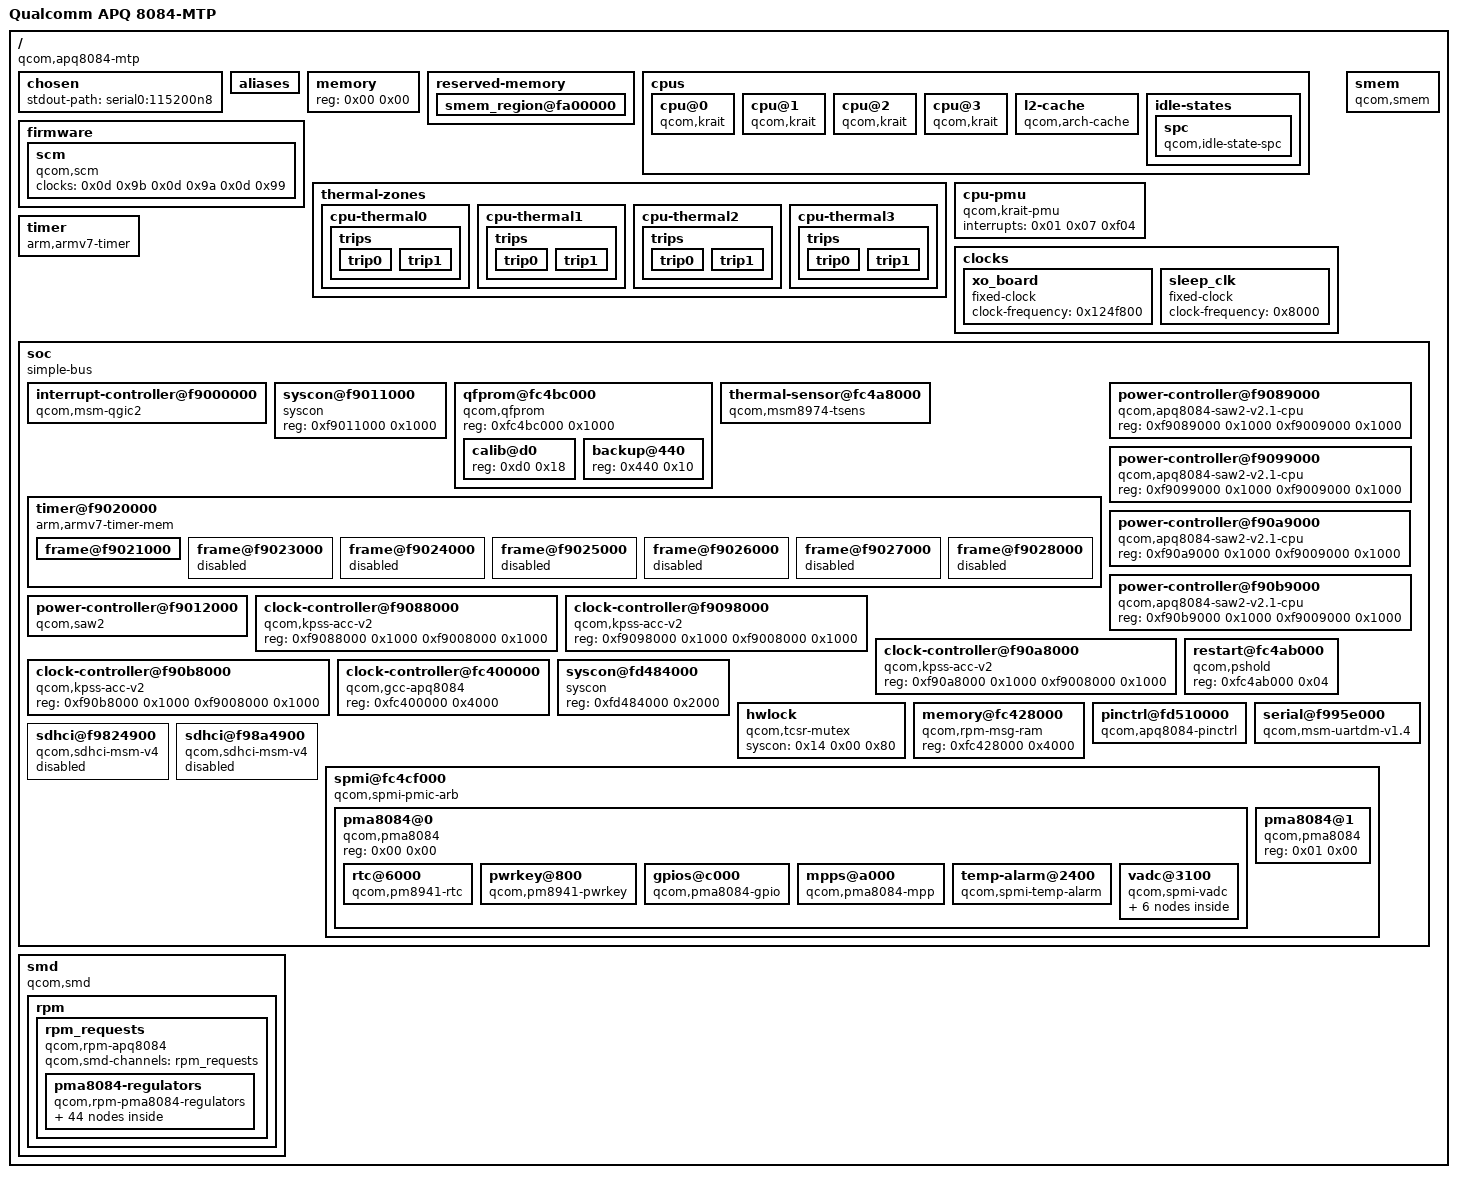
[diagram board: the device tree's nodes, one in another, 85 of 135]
/dts-v1/;

/ {
	#address-cells = <0x01>;
	#size-cells = <0x01>;
	model = "Qualcomm APQ 8084-MTP";
	compatible = "qcom,apq8084-mtp\0qcom,apq8084";
	interrupt-parent = <0x01>;

	chosen {
		stdout-path = "serial0:115200n8";
	};

	aliases {
		serial0 = "/soc/serial@f995e000";
		usid0 = "/soc/spmi@fc4cf000/pma8084@0";
	};

	memory {
		device_type = "memory";
		reg = <0x00 0x00>;
	};

	reserved-memory {
		#address-cells = <0x01>;
		#size-cells = <0x01>;
		ranges;

		smem_region@fa00000 {
			reg = <0xfa00000 0x200000>;
			no-map;
			phandle = <0x10>;
		};
	};

	cpus {
		#address-cells = <0x01>;
		#size-cells = <0x00>;

		cpu@0 {
			device_type = "cpu";
			compatible = "qcom,krait";
			reg = <0x00>;
			enable-method = "qcom,kpss-acc-v2";
			next-level-cache = <0x02>;
			qcom,acc = <0x03>;
			qcom,saw = <0x04>;
			cpu-idle-states = <0x05>;
		};

		cpu@1 {
			device_type = "cpu";
			compatible = "qcom,krait";
			reg = <0x01>;
			enable-method = "qcom,kpss-acc-v2";
			next-level-cache = <0x02>;
			qcom,acc = <0x06>;
			qcom,saw = <0x07>;
			cpu-idle-states = <0x05>;
		};

		cpu@2 {
			device_type = "cpu";
			compatible = "qcom,krait";
			reg = <0x02>;
			enable-method = "qcom,kpss-acc-v2";
			next-level-cache = <0x02>;
			qcom,acc = <0x08>;
			qcom,saw = <0x09>;
			cpu-idle-states = <0x05>;
		};

		cpu@3 {
			device_type = "cpu";
			compatible = "qcom,krait";
			reg = <0x03>;
			enable-method = "qcom,kpss-acc-v2";
			next-level-cache = <0x02>;
			qcom,acc = <0x0a>;
			qcom,saw = <0x0b>;
			cpu-idle-states = <0x05>;
		};

		l2-cache {
			compatible = "qcom,arch-cache";
			cache-level = <0x02>;
			qcom,saw = <0x0c>;
			phandle = <0x02>;
		};

		idle-states {

			spc {
				compatible = "qcom,idle-state-spc\0arm,idle-state";
				entry-latency-us = <0x96>;
				exit-latency-us = <0xc8>;
				min-residency-us = <0x7d0>;
				phandle = <0x05>;
			};
		};
	};

	firmware {

		scm {
			compatible = "qcom,scm";
			clocks = <0x0d 0x9b 0x0d 0x9a 0x0d 0x99>;
			clock-names = "core\0bus\0iface";
		};
	};

	thermal-zones {

		cpu-thermal0 {
			polling-delay-passive = <0xfa>;
			polling-delay = <0x3e8>;
			thermal-sensors = <0x0e 0x05>;

			trips {

				trip0 {
					temperature = <0x124f8>;
					hysteresis = <0x7d0>;
					type = "passive";
					phandle = <0x17>;
				};

				trip1 {
					temperature = <0x1adb0>;
					hysteresis = <0x7d0>;
					type = "critical";
					phandle = <0x18>;
				};
			};
		};

		cpu-thermal1 {
			polling-delay-passive = <0xfa>;
			polling-delay = <0x3e8>;
			thermal-sensors = <0x0e 0x06>;

			trips {

				trip0 {
					temperature = <0x124f8>;
					hysteresis = <0x7d0>;
					type = "passive";
					phandle = <0x19>;
				};

				trip1 {
					temperature = <0x1adb0>;
					hysteresis = <0x7d0>;
					type = "critical";
					phandle = <0x1a>;
				};
			};
		};

		cpu-thermal2 {
			polling-delay-passive = <0xfa>;
			polling-delay = <0x3e8>;
			thermal-sensors = <0x0e 0x07>;

			trips {

				trip0 {
					temperature = <0x124f8>;
					hysteresis = <0x7d0>;
					type = "passive";
					phandle = <0x1b>;
				};

				trip1 {
					temperature = <0x1adb0>;
					hysteresis = <0x7d0>;
					type = "critical";
					phandle = <0x1c>;
				};
			};
		};

		cpu-thermal3 {
			polling-delay-passive = <0xfa>;
			polling-delay = <0x3e8>;
			thermal-sensors = <0x0e 0x08>;

			trips {

				trip0 {
					temperature = <0x124f8>;
					hysteresis = <0x7d0>;
					type = "passive";
					phandle = <0x1d>;
				};

				trip1 {
					temperature = <0x1adb0>;
					hysteresis = <0x7d0>;
					type = "critical";
					phandle = <0x1e>;
				};
			};
		};
	};

	cpu-pmu {
		compatible = "qcom,krait-pmu";
		interrupts = <0x01 0x07 0xf04>;
	};

	clocks {

		xo_board {
			compatible = "fixed-clock";
			#clock-cells = <0x00>;
			clock-frequency = <0x124f800>;
		};

		sleep_clk {
			compatible = "fixed-clock";
			#clock-cells = <0x00>;
			clock-frequency = <0x8000>;
		};
	};

	timer {
		compatible = "arm,armv7-timer";
		interrupts = <0x01 0x02 0xf08 0x01 0x03 0xf08 0x01 0x04 0xf08 0x01 0x01 0xf08>;
		clock-frequency = <0x124f800>;
	};

	smem {
		compatible = "qcom,smem";
		qcom,rpm-msg-ram = <0x0f>;
		memory-region = <0x10>;
		hwlocks = <0x11 0x03>;
	};

	soc {
		#address-cells = <0x01>;
		#size-cells = <0x01>;
		ranges;
		compatible = "simple-bus";
		phandle = <0x1f>;

		interrupt-controller@f9000000 {
			compatible = "qcom,msm-qgic2";
			interrupt-controller;
			#interrupt-cells = <0x03>;
			reg = <0xf9000000 0x1000 0xf9002000 0x1000>;
			phandle = <0x01>;
		};

		syscon@f9011000 {
			compatible = "syscon";
			reg = <0xf9011000 0x1000>;
			phandle = <0x16>;
		};

		qfprom@fc4bc000 {
			#address-cells = <0x01>;
			#size-cells = <0x01>;
			compatible = "qcom,qfprom";
			reg = <0xfc4bc000 0x1000>;
			phandle = <0x20>;

			calib@d0 {
				reg = <0xd0 0x18>;
				phandle = <0x12>;
			};

			backup@440 {
				reg = <0x440 0x10>;
				phandle = <0x13>;
			};
		};

		thermal-sensor@fc4a8000 {
			compatible = "qcom,msm8974-tsens";
			reg = <0xfc4a8000 0x2000>;
			nvmem-cells = <0x12 0x13>;
			nvmem-cell-names = "calib\0calib_backup";
			#thermal-sensor-cells = <0x01>;
			phandle = <0x0e>;
		};

		timer@f9020000 {
			#address-cells = <0x01>;
			#size-cells = <0x01>;
			ranges;
			compatible = "arm,armv7-timer-mem";
			reg = <0xf9020000 0x1000>;
			clock-frequency = <0x124f800>;

			frame@f9021000 {
				frame-number = <0x00>;
				interrupts = <0x00 0x08 0x04 0x00 0x07 0x04>;
				reg = <0xf9021000 0x1000 0xf9022000 0x1000>;
			};

			frame@f9023000 {
				frame-number = <0x01>;
				interrupts = <0x00 0x09 0x04>;
				reg = <0xf9023000 0x1000>;
				status = "disabled";
			};

			frame@f9024000 {
				frame-number = <0x02>;
				interrupts = <0x00 0x0a 0x04>;
				reg = <0xf9024000 0x1000>;
				status = "disabled";
			};

			frame@f9025000 {
				frame-number = <0x03>;
				interrupts = <0x00 0x0b 0x04>;
				reg = <0xf9025000 0x1000>;
				status = "disabled";
			};

			frame@f9026000 {
				frame-number = <0x04>;
				interrupts = <0x00 0x0c 0x04>;
				reg = <0xf9026000 0x1000>;
				status = "disabled";
			};

			frame@f9027000 {
				frame-number = <0x05>;
				interrupts = <0x00 0x0d 0x04>;
				reg = <0xf9027000 0x1000>;
				status = "disabled";
			};

			frame@f9028000 {
				frame-number = <0x06>;
				interrupts = <0x00 0x0e 0x04>;
				reg = <0xf9028000 0x1000>;
				status = "disabled";
			};
		};

		power-controller@f9089000 {
			compatible = "qcom,apq8084-saw2-v2.1-cpu\0qcom,saw2";
			reg = <0xf9089000 0x1000 0xf9009000 0x1000>;
			phandle = <0x04>;
		};

		power-controller@f9099000 {
			compatible = "qcom,apq8084-saw2-v2.1-cpu\0qcom,saw2";
			reg = <0xf9099000 0x1000 0xf9009000 0x1000>;
			phandle = <0x07>;
		};

		power-controller@f90a9000 {
			compatible = "qcom,apq8084-saw2-v2.1-cpu\0qcom,saw2";
			reg = <0xf90a9000 0x1000 0xf9009000 0x1000>;
			phandle = <0x09>;
		};

		power-controller@f90b9000 {
			compatible = "qcom,apq8084-saw2-v2.1-cpu\0qcom,saw2";
			reg = <0xf90b9000 0x1000 0xf9009000 0x1000>;
			phandle = <0x0b>;
		};

		power-controller@f9012000 {
			compatible = "qcom,saw2";
			reg = <0xf9012000 0x1000>;
			regulator;
			phandle = <0x0c>;
		};

		clock-controller@f9088000 {
			compatible = "qcom,kpss-acc-v2";
			reg = <0xf9088000 0x1000 0xf9008000 0x1000>;
			phandle = <0x03>;
		};

		clock-controller@f9098000 {
			compatible = "qcom,kpss-acc-v2";
			reg = <0xf9098000 0x1000 0xf9008000 0x1000>;
			phandle = <0x06>;
		};

		clock-controller@f90a8000 {
			compatible = "qcom,kpss-acc-v2";
			reg = <0xf90a8000 0x1000 0xf9008000 0x1000>;
			phandle = <0x08>;
		};

		clock-controller@f90b8000 {
			compatible = "qcom,kpss-acc-v2";
			reg = <0xf90b8000 0x1000 0xf9008000 0x1000>;
			phandle = <0x0a>;
		};

		restart@fc4ab000 {
			compatible = "qcom,pshold";
			reg = <0xfc4ab000 0x04>;
		};

		clock-controller@fc400000 {
			compatible = "qcom,gcc-apq8084";
			#clock-cells = <0x01>;
			#reset-cells = <0x01>;
			#power-domain-cells = <0x01>;
			reg = <0xfc400000 0x4000>;
			phandle = <0x0d>;
		};

		syscon@fd484000 {
			compatible = "syscon";
			reg = <0xfd484000 0x2000>;
			phandle = <0x14>;
		};

		hwlock {
			compatible = "qcom,tcsr-mutex";
			syscon = <0x14 0x00 0x80>;
			#hwlock-cells = <0x01>;
			phandle = <0x11>;
		};

		memory@fc428000 {
			compatible = "qcom,rpm-msg-ram";
			reg = <0xfc428000 0x4000>;
			phandle = <0x0f>;
		};

		pinctrl@fd510000 {
			compatible = "qcom,apq8084-pinctrl";
			reg = <0xfd510000 0x4000>;
			gpio-controller;
			#gpio-cells = <0x02>;
			interrupt-controller;
			#interrupt-cells = <0x02>;
			interrupts = <0x00 0xd0 0x00>;
			phandle = <0x21>;
		};

		serial@f995e000 {
			compatible = "qcom,msm-uartdm-v1.4\0qcom,msm-uartdm";
			reg = <0xf995e000 0x1000>;
			interrupts = <0x00 0x72 0x00>;
			clocks = <0x0d 0x8e 0x0d 0x7e>;
			clock-names = "core\0iface";
			status = "okay";
			phandle = <0x22>;
		};

		sdhci@f9824900 {
			compatible = "qcom,sdhci-msm-v4";
			reg = <0xf9824900 0x11c 0xf9824000 0x800>;
			reg-names = "hc_mem\0core_mem";
			interrupts = <0x00 0x7b 0x00 0x00 0x8a 0x00>;
			interrupt-names = "hc_irq\0pwr_irq";
			clocks = <0x0d 0xf8 0x0d 0xf7>;
			clock-names = "core\0iface";
			status = "disabled";
		};

		sdhci@f98a4900 {
			compatible = "qcom,sdhci-msm-v4";
			reg = <0xf98a4900 0x11c 0xf98a4000 0x800>;
			reg-names = "hc_mem\0core_mem";
			interrupts = <0x00 0x7d 0x00 0x00 0xdd 0x00>;
			interrupt-names = "hc_irq\0pwr_irq";
			clocks = <0x0d 0xfc 0x0d 0xfb>;
			clock-names = "core\0iface";
			status = "disabled";
		};

		spmi@fc4cf000 {
			compatible = "qcom,spmi-pmic-arb";
			reg-names = "core\0intr\0cnfg";
			reg = <0xfc4cf000 0x1000 0xfc4cb000 0x1000 0xfc4ca000 0x1000>;
			interrupt-names = "periph_irq";
			interrupts = <0x00 0xbe 0x00>;
			qcom,ee = <0x00>;
			qcom,channel = <0x00>;
			#address-cells = <0x02>;
			#size-cells = <0x00>;
			interrupt-controller;
			#interrupt-cells = <0x04>;
			phandle = <0x23>;

			pma8084@0 {
				compatible = "qcom,pma8084\0qcom,spmi-pmic";
				reg = <0x00 0x00>;
				#address-cells = <0x01>;
				#size-cells = <0x00>;
				phandle = <0x24>;

				rtc@6000 {
					compatible = "qcom,pm8941-rtc";
					reg = <0x6000 0x6100>;
					reg-names = "rtc\0alarm";
					interrupts = <0x00 0x61 0x01 0x01>;
				};

				pwrkey@800 {
					compatible = "qcom,pm8941-pwrkey";
					reg = <0x800>;
					interrupts = <0x00 0x08 0x00 0x03>;
					debounce = <0x3d09>;
					bias-pull-up;
				};

				gpios@c000 {
					compatible = "qcom,pma8084-gpio\0qcom,spmi-gpio";
					reg = <0xc000>;
					gpio-controller;
					#gpio-cells = <0x02>;
					interrupts = <0x00 0xc0 0x00 0x00 0x00 0xc1 0x00 0x00 0x00 0xc2 0x00 0x00 0x00 0xc3 0x00 0x00 0x00 0xc4 0x00 0x00 0x00 0xc5 0x00 0x00 0x00 0xc6 0x00 0x00 0x00 0xc7 0x00 0x00 0x00 0xc8 0x00 0x00 0x00 0xc9 0x00 0x00 0x00 0xca 0x00 0x00 0x00 0xcb 0x00 0x00 0x00 0xcc 0x00 0x00 0x00 0xcd 0x00 0x00 0x00 0xce 0x00 0x00 0x00 0xcf 0x00 0x00 0x00 0xd0 0x00 0x00 0x00 0xd1 0x00 0x00 0x00 0xd2 0x00 0x00 0x00 0xd3 0x00 0x00 0x00 0xd4 0x00 0x00 0x00 0xd5 0x00 0x00>;
					phandle = <0x25>;
				};

				mpps@a000 {
					compatible = "qcom,pma8084-mpp\0qcom,spmi-mpp";
					reg = <0xa000>;
					gpio-controller;
					#gpio-cells = <0x02>;
					interrupts = <0x00 0xa0 0x00 0x00 0x00 0xa1 0x00 0x00 0x00 0xa2 0x00 0x00 0x00 0xa3 0x00 0x00 0x00 0xa4 0x00 0x00 0x00 0xa5 0x00 0x00 0x00 0xa6 0x00 0x00 0x00 0xa7 0x00 0x00>;
					phandle = <0x26>;
				};

				temp-alarm@2400 {
					compatible = "qcom,spmi-temp-alarm";
					reg = <0x2400>;
					interrupts = <0x00 0x24 0x00 0x01>;
					#thermal-sensor-cells = <0x00>;
					io-channels = <0x15 0x08>;
					io-channel-names = "thermal";
					phandle = <0x27>;
				};

				vadc@3100 {
					compatible = "qcom,spmi-vadc";
					reg = <0x3100>;
					interrupts = <0x00 0x31 0x00 0x01>;
					#address-cells = <0x01>;
					#size-cells = <0x00>;
					#io-channel-cells = <0x01>;
					io-channel-ranges;
					phandle = <0x15>;

					die_temp {
						reg = <0x08>;
					};

					ref_625mv {
						reg = <0x09>;
					};

					ref_1250v {
						reg = <0x0a>;
					};

					ref_buf_625mv {
						reg = <0x0c>;
					};

					ref_gnd {
						reg = <0x0e>;
					};

					ref_vdd {
						reg = <0x0f>;
					};
				};
			};

			pma8084@1 {
				compatible = "qcom,pma8084\0qcom,spmi-pmic";
				reg = <0x01 0x00>;
				#address-cells = <0x01>;
				#size-cells = <0x00>;
				phandle = <0x28>;
			};
		};
	};

	smd {
		compatible = "qcom,smd";

		rpm {
			interrupts = <0x00 0xa8 0x01>;
			qcom,ipc = <0x16 0x08 0x00>;
			qcom,smd-edge = <0x0f>;

			rpm_requests {
				compatible = "qcom,rpm-apq8084";
				qcom,smd-channels = "rpm_requests";

				pma8084-regulators {
					compatible = "qcom,rpm-pma8084-regulators";

					s1 {
						phandle = <0x29>;
					};

					s2 {
						phandle = <0x2a>;
					};

					s3 {
						phandle = <0x2b>;
					};

					s4 {
						phandle = <0x2c>;
					};

					s5 {
						phandle = <0x2d>;
					};

					s6 {
						phandle = <0x2e>;
					};

					s7 {
						phandle = <0x2f>;
					};

					s8 {
						phandle = <0x30>;
					};

					s9 {
						phandle = <0x31>;
					};

					s10 {
						phandle = <0x32>;
					};

					s11 {
						phandle = <0x33>;
					};

					s12 {
						phandle = <0x34>;
					};

					l1 {
						phandle = <0x35>;
					};

					l2 {
						phandle = <0x36>;
					};

					l3 {
						phandle = <0x37>;
					};

					l4 {
						phandle = <0x38>;
					};

					l5 {
						phandle = <0x39>;
					};

					l6 {
						phandle = <0x3a>;
					};

					l7 {
						phandle = <0x3b>;
					};

					l8 {
						phandle = <0x3c>;
					};

					l9 {
						phandle = <0x3d>;
					};

					l10 {
						phandle = <0x3e>;
					};

					l11 {
						phandle = <0x3f>;
					};

					l12 {
						phandle = <0x40>;
					};

					l13 {
						phandle = <0x41>;
					};

					l14 {
						phandle = <0x42>;
					};

					l15 {
						phandle = <0x43>;
					};

					l16 {
						phandle = <0x44>;
					};

					l17 {
						phandle = <0x45>;
					};

					l18 {
						phandle = <0x46>;
					};

					l19 {
						phandle = <0x47>;
					};

					l20 {
						phandle = <0x48>;
					};

					l21 {
						phandle = <0x49>;
					};

					l22 {
						phandle = <0x4a>;
					};

					l23 {
						phandle = <0x4b>;
					};

					l24 {
						phandle = <0x4c>;
					};

					l25 {
						phandle = <0x4d>;
					};

					l26 {
						phandle = <0x4e>;
					};

					l27 {
						phandle = <0x4f>;
					};

					lvs1 {
						phandle = <0x50>;
					};

					lvs2 {
						phandle = <0x51>;
					};

					lvs3 {
						phandle = <0x52>;
					};

					lvs4 {
						phandle = <0x53>;
					};

					5vs1 {
						phandle = <0x54>;
					};
				};
			};
		};
	};

	__symbols__ {
		smem_mem = "/reserved-memory/smem_region@fa00000";
		L2 = "/cpus/l2-cache";
		CPU_SPC = "/cpus/idle-states/spc";
		cpu_alert0 = "/thermal-zones/cpu-thermal0/trips/trip0";
		cpu_crit0 = "/thermal-zones/cpu-thermal0/trips/trip1";
		cpu_alert1 = "/thermal-zones/cpu-thermal1/trips/trip0";
		cpu_crit1 = "/thermal-zones/cpu-thermal1/trips/trip1";
		cpu_alert2 = "/thermal-zones/cpu-thermal2/trips/trip0";
		cpu_crit2 = "/thermal-zones/cpu-thermal2/trips/trip1";
		cpu_alert3 = "/thermal-zones/cpu-thermal3/trips/trip0";
		cpu_crit3 = "/thermal-zones/cpu-thermal3/trips/trip1";
		soc = "/soc";
		intc = "/soc/interrupt-controller@f9000000";
		apcs = "/soc/syscon@f9011000";
		qfprom = "/soc/qfprom@fc4bc000";
		tsens_calib = "/soc/qfprom@fc4bc000/calib@d0";
		tsens_backup = "/soc/qfprom@fc4bc000/backup@440";
		tsens = "/soc/thermal-sensor@fc4a8000";
		saw0 = "/soc/power-controller@f9089000";
		saw1 = "/soc/power-controller@f9099000";
		saw2 = "/soc/power-controller@f90a9000";
		saw3 = "/soc/power-controller@f90b9000";
		saw_l2 = "/soc/power-controller@f9012000";
		acc0 = "/soc/clock-controller@f9088000";
		acc1 = "/soc/clock-controller@f9098000";
		acc2 = "/soc/clock-controller@f90a8000";
		acc3 = "/soc/clock-controller@f90b8000";
		gcc = "/soc/clock-controller@fc400000";
		tcsr_mutex_regs = "/soc/syscon@fd484000";
		tcsr_mutex = "/soc/hwlock";
		rpm_msg_ram = "/soc/memory@fc428000";
		tlmm = "/soc/pinctrl@fd510000";
		blsp2_uart2 = "/soc/serial@f995e000";
		spmi_bus = "/soc/spmi@fc4cf000";
		pma8084_0 = "/soc/spmi@fc4cf000/pma8084@0";
		pma8084_gpios = "/soc/spmi@fc4cf000/pma8084@0/gpios@c000";
		pma8084_mpps = "/soc/spmi@fc4cf000/pma8084@0/mpps@a000";
		pma8084_temp = "/soc/spmi@fc4cf000/pma8084@0/temp-alarm@2400";
		pma8084_vadc = "/soc/spmi@fc4cf000/pma8084@0/vadc@3100";
		pma8084_1 = "/soc/spmi@fc4cf000/pma8084@1";
		pma8084_s1 = "/smd/rpm/rpm_requests/pma8084-regulators/s1";
		pma8084_s2 = "/smd/rpm/rpm_requests/pma8084-regulators/s2";
		pma8084_s3 = "/smd/rpm/rpm_requests/pma8084-regulators/s3";
		pma8084_s4 = "/smd/rpm/rpm_requests/pma8084-regulators/s4";
		pma8084_s5 = "/smd/rpm/rpm_requests/pma8084-regulators/s5";
		pma8084_s6 = "/smd/rpm/rpm_requests/pma8084-regulators/s6";
		pma8084_s7 = "/smd/rpm/rpm_requests/pma8084-regulators/s7";
		pma8084_s8 = "/smd/rpm/rpm_requests/pma8084-regulators/s8";
		pma8084_s9 = "/smd/rpm/rpm_requests/pma8084-regulators/s9";
		pma8084_s10 = "/smd/rpm/rpm_requests/pma8084-regulators/s10";
		pma8084_s11 = "/smd/rpm/rpm_requests/pma8084-regulators/s11";
		pma8084_s12 = "/smd/rpm/rpm_requests/pma8084-regulators/s12";
		pma8084_l1 = "/smd/rpm/rpm_requests/pma8084-regulators/l1";
		pma8084_l2 = "/smd/rpm/rpm_requests/pma8084-regulators/l2";
		pma8084_l3 = "/smd/rpm/rpm_requests/pma8084-regulators/l3";
		pma8084_l4 = "/smd/rpm/rpm_requests/pma8084-regulators/l4";
		pma8084_l5 = "/smd/rpm/rpm_requests/pma8084-regulators/l5";
		pma8084_l6 = "/smd/rpm/rpm_requests/pma8084-regulators/l6";
		pma8084_l7 = "/smd/rpm/rpm_requests/pma8084-regulators/l7";
		pma8084_l8 = "/smd/rpm/rpm_requests/pma8084-regulators/l8";
		pma8084_l9 = "/smd/rpm/rpm_requests/pma8084-regulators/l9";
		pma8084_l10 = "/smd/rpm/rpm_requests/pma8084-regulators/l10";
		pma8084_l11 = "/smd/rpm/rpm_requests/pma8084-regulators/l11";
		pma8084_l12 = "/smd/rpm/rpm_requests/pma8084-regulators/l12";
		pma8084_l13 = "/smd/rpm/rpm_requests/pma8084-regulators/l13";
		pma8084_l14 = "/smd/rpm/rpm_requests/pma8084-regulators/l14";
		pma8084_l15 = "/smd/rpm/rpm_requests/pma8084-regulators/l15";
		pma8084_l16 = "/smd/rpm/rpm_requests/pma8084-regulators/l16";
		pma8084_l17 = "/smd/rpm/rpm_requests/pma8084-regulators/l17";
		pma8084_l18 = "/smd/rpm/rpm_requests/pma8084-regulators/l18";
		pma8084_l19 = "/smd/rpm/rpm_requests/pma8084-regulators/l19";
		pma8084_l20 = "/smd/rpm/rpm_requests/pma8084-regulators/l20";
		pma8084_l21 = "/smd/rpm/rpm_requests/pma8084-regulators/l21";
		pma8084_l22 = "/smd/rpm/rpm_requests/pma8084-regulators/l22";
		pma8084_l23 = "/smd/rpm/rpm_requests/pma8084-regulators/l23";
		pma8084_l24 = "/smd/rpm/rpm_requests/pma8084-regulators/l24";
		pma8084_l25 = "/smd/rpm/rpm_requests/pma8084-regulators/l25";
		pma8084_l26 = "/smd/rpm/rpm_requests/pma8084-regulators/l26";
		pma8084_l27 = "/smd/rpm/rpm_requests/pma8084-regulators/l27";
		pma8084_lvs1 = "/smd/rpm/rpm_requests/pma8084-regulators/lvs1";
		pma8084_lvs2 = "/smd/rpm/rpm_requests/pma8084-regulators/lvs2";
		pma8084_lvs3 = "/smd/rpm/rpm_requests/pma8084-regulators/lvs3";
		pma8084_lvs4 = "/smd/rpm/rpm_requests/pma8084-regulators/lvs4";
		pma8084_5vs1 = "/smd/rpm/rpm_requests/pma8084-regulators/5vs1";
	};
};
